VERSION ""

NS_ :

BS_:

BU_: ADU BCS_2 YAS SAS EPB_R EPS ABM GW GW_VCU GW_ICM GW_IHU GW_BCM ADU IDC IDC_VCU IDC_RMCU IDC_BCM IDC_ICM IDC_IHU ADU BCS_2 YAS SAS EPB_R EPS ABM GW GW_VCU GW_ICM GW_IHU GW_BCM ADU IDC IDC_VCU IDC_RMCU IDC_BCM IDC_ICM IDC_IHU ADU BCS_2 YAS SAS EPB_R EPS ABM GW GW_VCU GW_ICM GW_IHU GW_BCM

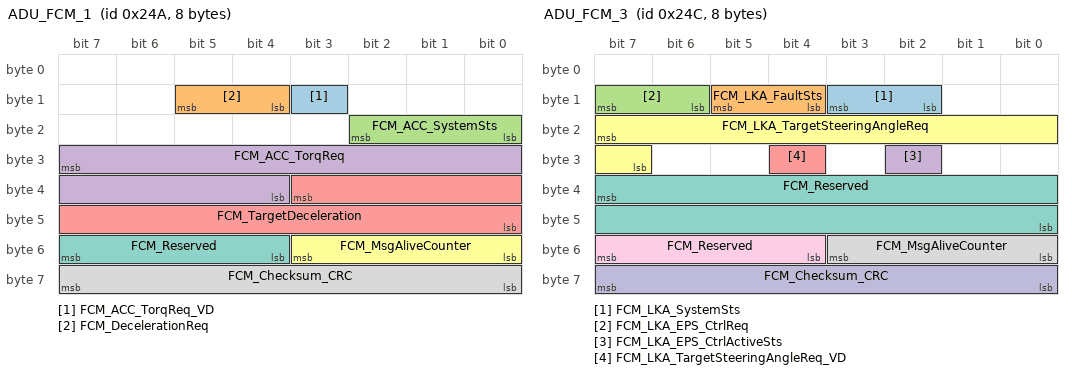
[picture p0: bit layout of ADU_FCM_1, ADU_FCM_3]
BO_ 586 ADU_FCM_1: 8 ADU
 SG_ FCM_ACC_TorqReq_VD : 11|1@0+ (1,0) [0|1] "" GW, GW_VCU
 SG_ FCM_DecelerationReq : 13|2@0+ (1,0) [0|3] "" BCS_2, GW, GW_VCU
 SG_ FCM_ACC_SystemSts : 18|3@0+ (1,0) [0|7] "" BCS_2, GW, GW_VCU, GW_ICM
 SG_ FCM_ACC_TorqReq : 31|12@0+ (5,-8000) [-8000|8000] "Nm" GW, GW_VCU
 SG_ FCM_TargetDeceleration : 35|12@0+ (0.01,-20) [-20|20] "m/s2" BCS_2
 SG_ FCM_MsgAliveCounter : 51|4@0+ (1,0) [0|14] "" BCS_2, GW_VCU
 SG_ FCM_Reserved : 55|4@0+ (1,0) [0|0] "" Vector__XXX
 SG_ FCM_Checksum_CRC : 63|8@0+ (1,0) [0|255] "" BCS_2, GW_VCU

BO_ 588 ADU_FCM_3: 8 ADU
 SG_ FCM_LKA_SystemSts : 11|2@0+ (1,0) [0|3] "" EPS, GW, GW_ICM
 SG_ FCM_LKA_FaultSts : 13|2@0+ (1,0) [0|3] "" GW, GW_ICM
 SG_ FCM_LKA_EPS_CtrlReq : 15|2@0+ (1,0) [0|3] "" EPS
 SG_ FCM_LKA_EPS_CtrlActiveSts : 26|1@0+ (1,0) [0|1] "" EPS
 SG_ FCM_LKA_TargetSteeringAngleReq_VD : 28|1@0+ (1,0) [0|1] "" EPS
 SG_ FCM_LKA_TargetSteeringAngleReq : 23|9@0+ (0.1,-25) [-25|25] "deg" EPS
 SG_ FCM_Reserved : 39|16@0+ (1,0) [0|0] "" Vector__XXX
 SG_ FCM_MsgAliveCounter : 51|4@0+ (1,0) [0|14] "" EPS
 SG_ FCM_Reserved : 55|4@0+ (1,0) [0|0] "" Vector__XXX
 SG_ FCM_Checksum_CRC : 63|8@0+ (1,0) [0|255] "" EPS

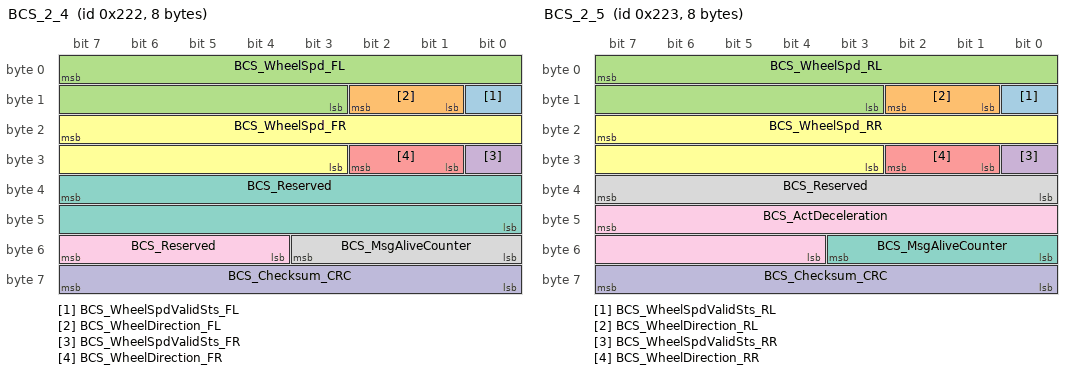
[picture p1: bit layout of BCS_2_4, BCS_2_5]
BO_ 546 BCS_2_4: 8 BCS_2
 SG_ BCS_WheelSpdValidSts_FL : 8|1@0+ (1,0) [0|1] "" ADU, EPB_R
 SG_ BCS_WheelDirection_FL : 10|2@0+ (1,0) [0|3] "" ADU, EPB_R
 SG_ BCS_WheelSpd_FL : 7|13@0+ (0.0625,0) [0|500] "km/h" ADU, EPB_R
 SG_ BCS_WheelSpdValidSts_FR : 24|1@0+ (1,0) [0|1] "" ADU, EPB_R
 SG_ BCS_WheelDirection_FR : 26|2@0+ (1,0) [0|3] "" ADU, EPB_R
 SG_ BCS_WheelSpd_FR : 23|13@0+ (0.0625,0) [0|500] "km/h" ADU, EPB_R
 SG_ BCS_Reserved : 39|16@0+ (1,0) [0|0] "" Vector__XXX
 SG_ BCS_MsgAliveCounter : 51|4@0+ (1,0) [0|14] "" ADU, EPB_R
 SG_ BCS_Reserved : 55|4@0+ (1,0) [0|0] "" Vector__XXX
 SG_ BCS_Checksum_CRC : 63|8@0+ (1,0) [0|255] "" ADU, EPB_R

BO_ 547 BCS_2_5: 8 BCS_2
 SG_ BCS_WheelSpdValidSts_RL : 8|1@0+ (1,0) [0|1] "" ADU, EPB_R
 SG_ BCS_WheelDirection_RL : 10|2@0+ (1,0) [0|3] "" ADU, EPB_R
 SG_ BCS_WheelSpd_RL : 7|13@0+ (0.0625,0) [0|500] "km/h" ADU, EPB_R
 SG_ BCS_WheelSpdValidSts_RR : 24|1@0+ (1,0) [0|1] "" ADU, EPB_R
 SG_ BCS_WheelDirection_RR : 26|2@0+ (1,0) [0|3] "" ADU, EPB_R
 SG_ BCS_WheelSpd_RR : 23|13@0+ (0.0625,0) [0|500] "km/h" ADU, EPB_R
 SG_ BCS_MsgAliveCounter : 51|4@0+ (1,0) [0|14] "" EPB_R
 SG_ BCS_Reserved : 39|8@0+ (1,0) [0|0] "" ADU
 SG_ BCS_ActDeceleration : 47|12@0+ (0.01,-20) [-20|20] "m/s2" Vector__XXX
 SG_ BCS_Checksum_CRC : 63|8@0+ (1,0) [0|255] "" ADU, EPB_R

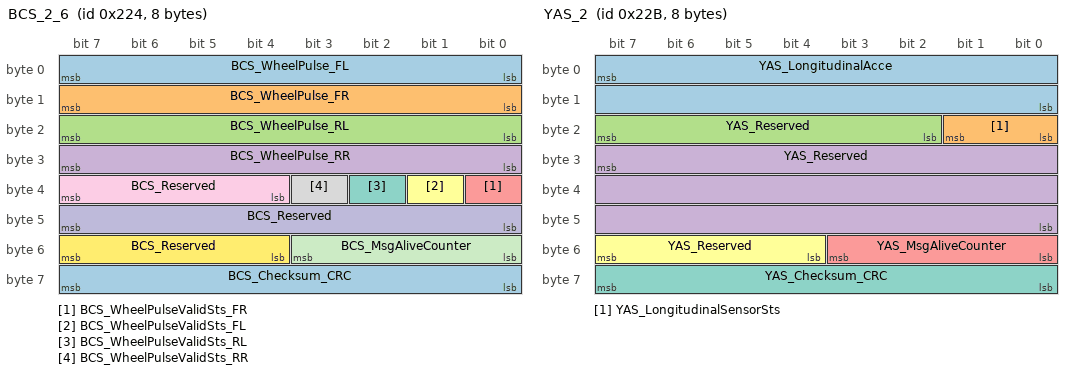
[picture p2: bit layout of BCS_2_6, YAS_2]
BO_ 548 BCS_2_6: 8 BCS_2
 SG_ BCS_WheelPulse_FL : 7|8@0+ (1,0) [0|254] "" ADU, EPB_R
 SG_ BCS_WheelPulse_FR : 15|8@0+ (1,0) [0|254] "" ADU, EPB_R
 SG_ BCS_WheelPulse_RL : 23|8@0+ (1,0) [0|254] "" ADU, EPB_R
 SG_ BCS_WheelPulse_RR : 31|8@0+ (1,0) [0|254] "" ADU, EPB_R
 SG_ BCS_WheelPulseValidSts_FR : 32|1@0+ (1,0) [0|1] "" ADU, EPB_R
 SG_ BCS_WheelPulseValidSts_FL : 33|1@0+ (1,0) [0|1] "" ADU, EPB_R
 SG_ BCS_WheelPulseValidSts_RL : 34|1@0+ (1,0) [0|1] "" ADU, EPB_R
 SG_ BCS_WheelPulseValidSts_RR : 35|1@0+ (1,0) [0|1] "" ADU, EPB_R
 SG_ BCS_Reserved : 39|4@0+ (1,0) [0|0] "" Vector__XXX
 SG_ BCS_Reserved : 47|8@0+ (1,0) [0|0] "" Vector__XXX
 SG_ BCS_MsgAliveCounter : 51|4@0+ (1,0) [0|14] "" ADU, EPB_R
 SG_ BCS_Reserved : 55|4@0+ (1,0) [0|0] "" Vector__XXX
 SG_ BCS_Checksum_CRC : 63|8@0+ (1,0) [0|255] "" ADU, EPB_R

BO_ 555 YAS_2: 8 YAS
 SG_ YAS_LongitudinalAcce : 7|16@0+ (0.001,-2) [-2|2] "g" ADU, GW
 SG_ YAS_LongitudinalSensorSts : 17|2@0+ (1,0) [0|3] "" ADU, GW
 SG_ YAS_Reserved : 23|6@0+ (1,0) [0|0] "" Vector__XXX
 SG_ YAS_Reserved : 31|24@0+ (1,0) [0|0] "" Vector__XXX
 SG_ YAS_MsgAliveCounter : 51|4@0+ (1,0) [0|14] "" ADU, GW
 SG_ YAS_Reserved : 55|4@0+ (1,0) [0|0] "" Vector__XXX
 SG_ YAS_Checksum_CRC : 63|8@0+ (1,0) [0|255] "" ADU, GW

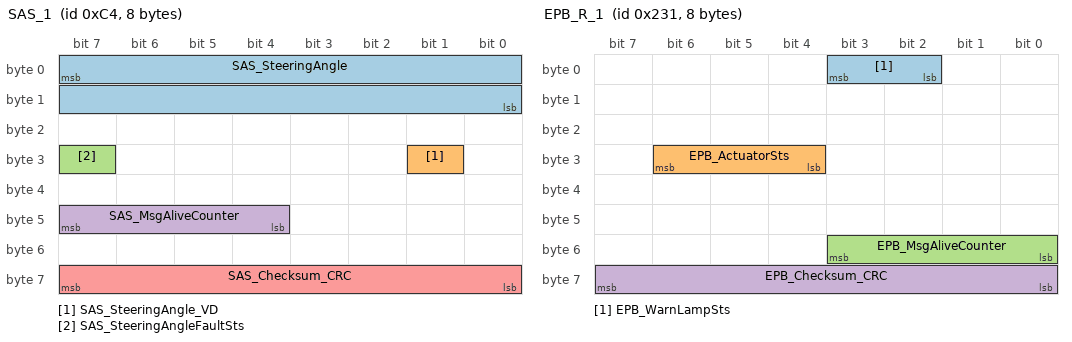
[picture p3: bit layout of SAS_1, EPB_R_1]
BO_ 196 SAS_1: 8 SAS
 SG_ SAS_SteeringAngle : 7|16@0+ (0.0625,-2048) [-2048|2047] "deg" ADU, BCS_2
 SG_ SAS_SteeringAngle_VD : 25|1@0+ (1,0) [0|1] "" ADU, BCS_2
 SG_ SAS_SteeringAngleFaultSts : 31|1@0+ (1,0) [0|1] "" ADU, BCS_2
 SG_ SAS_MsgAliveCounter : 47|4@0+ (1,0) [0|15] "" ADU, BCS_2
 SG_ SAS_Checksum_CRC : 63|8@0+ (1,0) [0|255] "" ADU, BCS_2

BO_ 561 EPB_R_1: 8 EPB_R
 SG_ EPB_WarnLampSts : 3|2@0+ (1,0) [0|3] "" ADU
 SG_ EPB_ActuatorSts : 30|3@0+ (1,0) [0|7] "" ADU
 SG_ EPB_MsgAliveCounter : 51|4@0+ (1,0) [0|14] "" ADU
 SG_ EPB_Checksum_CRC : 63|8@0+ (1,0) [0|255] "" ADU

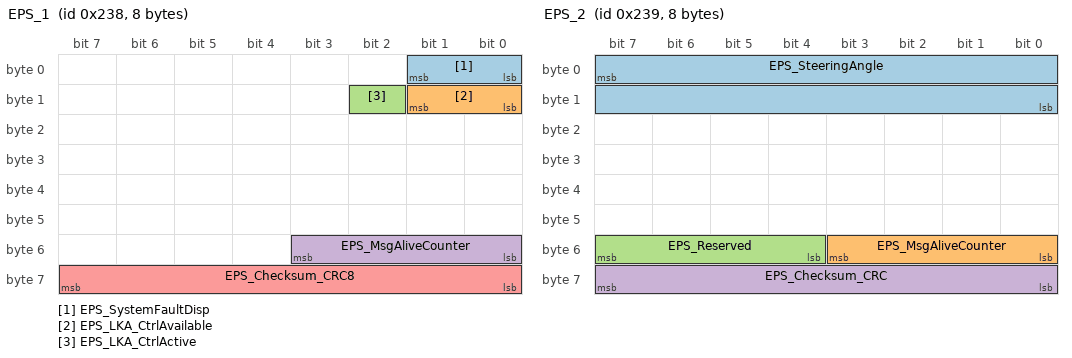
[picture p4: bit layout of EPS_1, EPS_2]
BO_ 568 EPS_1: 8 EPS
 SG_ EPS_SystemFaultDisp : 1|2@0+ (1,0) [0|3] "" ADU
 SG_ EPS_LKA_CtrlAvailable : 9|2@0+ (1,0) [0|3] "" ADU
 SG_ EPS_LKA_CtrlActive : 10|1@0+ (1,0) [0|1] "" ADU
 SG_ EPS_MsgAliveCounter : 51|4@0+ (1,0) [0|14] "" Vector__XXX
 SG_ EPS_Checksum_CRC8 : 63|8@0+ (1,0) [0|255] "" Vector__XXX

BO_ 569 EPS_2: 8 EPS
 SG_ EPS_SteeringAngle : 7|16@0+ (0.1,-720) [-720|720] "deg" Vector__XXX
 SG_ EPS_MsgAliveCounter : 51|4@0+ (1,0) [0|15] "" Vector__XXX
 SG_ EPS_Reserved : 55|4@0+ (1,0) [0|0] "" Vector__XXX
 SG_ EPS_Checksum_CRC : 63|8@0+ (1,0) [0|255] "" Vector__XXX

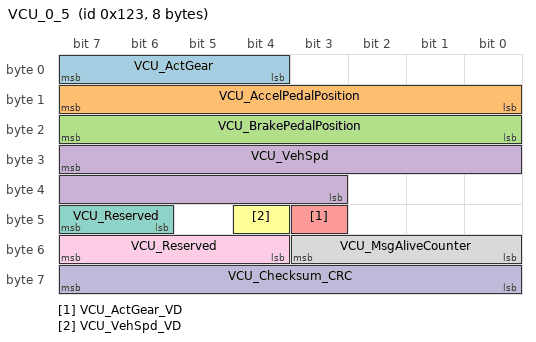
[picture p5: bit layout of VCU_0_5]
BO_ 291 VCU_0_5: 8 GW
 SG_ VCU_ActGear : 7|4@0+ (1,0) [0|15] "" ADU
 SG_ VCU_AccelPedalPosition : 15|8@0+ (0.4,0) [0|100] "" ADU
 SG_ VCU_BrakePedalPosition : 23|8@0+ (0.4,0) [0|100] "" Vector__XXX
 SG_ VCU_VehSpd : 31|13@0+ (0.0625,0) [0|500] "km/h" ADU
 SG_ VCU_ActGear_VD : 43|1@0+ (1,0) [0|1] "" ADU
 SG_ VCU_VehSpd_VD : 44|1@0+ (1,0) [0|1] "" ADU
 SG_ VCU_Reserved : 47|2@0+ (1,0) [0|0] "" Vector__XXX
 SG_ VCU_MsgAliveCounter : 51|4@0+ (1,0) [0|14] "" ADU
 SG_ VCU_Reserved : 55|4@0+ (1,0) [0|0] "" Vector__XXX
 SG_ VCU_Checksum_CRC : 63|8@0+ (1,0) [0|255] "" ADU

BA_DEF_  "BusType" STRING ;
BA_DEF_DEF_  "BusType" "CAN";
